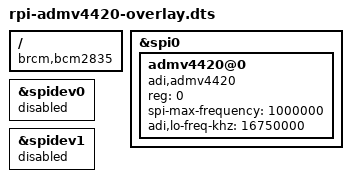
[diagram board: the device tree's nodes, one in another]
/dts-v1/;
/plugin/;
/ {
	compatible = "brcm,bcm2835", "brcm,bcm2708", "brcm,bcm2709";

	fragment@0 {
		target = <&spi0>;
		__overlay__ {
			#address-cells = <1>;
			#size-cells = <0>;
			status = "okay";

			admv4420@0 {
				compatible = "adi,admv4420";
				reg = <0>;
				spi-max-frequency = <1000000>;
				adi,lo-freq-khz = <16750000>;
				// adi,ref_ext_single_ended_en;
			};
		};
	};

	fragment@1 {
		target = <&spidev0>;
		__overlay__ {
			status = "disabled";
		};
	};

	fragment@2 {
		target = <&spidev1>;
		__overlay__ {
			status = "disabled";
		};
	};
};
